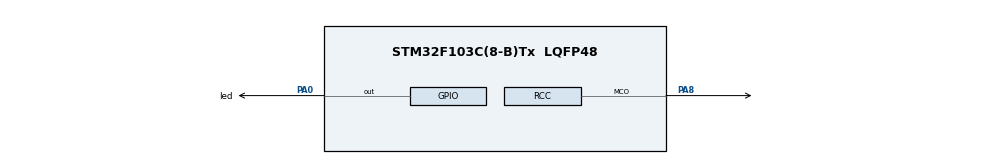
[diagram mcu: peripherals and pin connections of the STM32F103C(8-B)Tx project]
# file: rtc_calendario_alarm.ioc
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Mcu.Family=STM32F1
Mcu.Name=STM32F103C(8-B)Tx
Mcu.Package=LQFP48
NVIC.PriorityGroup=NVIC_PRIORITYGROUP_4
PA0-WKUP.GPIO_Label=led
PA0-WKUP.Signal=GPIO_Output
PA8.Mode=Clock-out
PA8.Signal=RCC_MCO
PC14-OSC32_IN.Mode=LSE-External-Oscillator
PC14-OSC32_IN.Signal=RCC_OSC32_IN
PC15-OSC32_OUT.Mode=LSE-External-Oscillator
PC15-OSC32_OUT.Signal=RCC_OSC32_OUT
ProjectManager.HeapSize=0x200
ProjectManager.StackSize=0x400
ProjectManager.TargetToolchain=STM32CubeIDE
RCC.APB1Freq_Value=8000000
RCC.APB2Freq_Value=8000000
RCC.RTCClockSelection=RCC_RTCCLKSOURCE_LSE
RTC.Format=RTC_FORMAT_BIN
VP_RTC_VS_RTC_Activate.Mode=RTC_Enabled
VP_RTC_VS_RTC_Calendar.Mode=RTC_Calendar
board=custom

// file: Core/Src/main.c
/* USER CODE BEGIN Header */
/**
  ******************************************************************************
  * @file           : main.c
  * @brief          : Main program body
  ******************************************************************************
  * @attention
  *
  * Copyright (c) 2023 STMicroelectronics.
  * All rights reserved.
  *
  * This software is licensed under terms that can be found in the LICENSE file
  * in the root directory of this software component.
  * If no LICENSE file comes with this software, it is provided AS-IS.
  *
  ******************************************************************************
  */
/* USER CODE END Header */
#include "main.h"

RTC_HandleTypeDef hrtc;

/* USER CODE BEGIN PV */
RTC_DateTypeDef sData;
RTC_TimeTypeDef sTempo;
uint8_t dia;
uint8_t semana;
uint8_t mes;
uint8_t ano;
uint8_t seg;
uint8_t min;
uint8_t hora;

/* USER CODE END PV */

void SystemClock_Config(void);
static void MX_GPIO_Init(void);
static void MX_RTC_Init(void);

int main(void)
{

  /* MCU Configuration--------------------------------------------------------*/

  /* Reset of all peripherals, Initializes the Flash interface and the Systick. */
  HAL_Init();

  /* Configure the system clock */
  SystemClock_Config();

  /* Initialize all configured peripherals */
  MX_GPIO_Init();
  MX_RTC_Init();
  /* USER CODE BEGIN 2 */
  sData.Date = 25;
  sData.Month = 5;
  sData.WeekDay = 6;
  sData.Year = 23;
  HAL_RTC_SetDate(&hrtc, &sData, FORMAT_BIN);

  sTempo.Seconds = 50;
  sTempo.Minutes = 59;
  sTempo.Hours = 23;
  HAL_RTC_SetTime(&hrtc, &sTempo, FORMAT_BIN);

  /* USER CODE END 2 */

  /* Infinite loop */
  /* USER CODE BEGIN WHILE */
  while (1)
  {
	  HAL_RTC_GetDate(&hrtc, &sData, FORMAT_BIN);
	  dia = sData.Date;
	  HAL_RTC_GetDate(&hrtc, &sData, FORMAT_BIN);
	  mes = sData.Month;
	  HAL_RTC_GetDate(&hrtc, &sData, FORMAT_BIN);
	  semana = sData.WeekDay;
	  HAL_RTC_GetDate(&hrtc, &sData, FORMAT_BIN);
	  ano = sData.Year;

	  HAL_RTC_GetTime(&hrtc, &sTempo, FORMAT_BIN);
	  seg = sTempo.Seconds;
	  HAL_RTC_GetTime(&hrtc, &sTempo, FORMAT_BIN);
	  min = sTempo.Minutes;
	  HAL_RTC_GetTime(&hrtc, &sTempo, FORMAT_BIN);
	  ano = sTempo.Hours;

	  if(seg == 0){
		  HAL_GPIO_WritePin(GPIOA,led_Pin, 1);
	  }
	  if(seg == 1){
		  HAL_GPIO_WritePin(GPIOA,led_Pin, 0);
	  }

    /* USER CODE END WHILE */

  }
}

void SystemClock_Config(void)
{
  RCC_OscInitTypeDef RCC_OscInitStruct = {0};
  RCC_ClkInitTypeDef RCC_ClkInitStruct = {0};
  RCC_PeriphCLKInitTypeDef PeriphClkInit = {0};

  /** Initializes the RCC Oscillators according to the specified parameters
  * in the RCC_OscInitTypeDef structure.
  */
  RCC_OscInitStruct.OscillatorType = RCC_OSCILLATORTYPE_HSI|RCC_OSCILLATORTYPE_LSE;
  RCC_OscInitStruct.LSEState = RCC_LSE_ON;
  RCC_OscInitStruct.HSIState = RCC_HSI_ON;
  RCC_OscInitStruct.HSICalibrationValue = RCC_HSICALIBRATION_DEFAULT;
  RCC_OscInitStruct.PLL.PLLState = RCC_PLL_NONE;
  if (HAL_RCC_OscConfig(&RCC_OscInitStruct) != HAL_OK)
  {
    Error_Handler();
  }

  /** Initializes the CPU, AHB and APB buses clocks
  */
  RCC_ClkInitStruct.ClockType = RCC_CLOCKTYPE_HCLK|RCC_CLOCKTYPE_SYSCLK
                              |RCC_CLOCKTYPE_PCLK1|RCC_CLOCKTYPE_PCLK2;
  RCC_ClkInitStruct.SYSCLKSource = RCC_SYSCLKSOURCE_HSI;
  RCC_ClkInitStruct.AHBCLKDivider = RCC_SYSCLK_DIV1;
  RCC_ClkInitStruct.APB1CLKDivider = RCC_HCLK_DIV1;
  RCC_ClkInitStruct.APB2CLKDivider = RCC_HCLK_DIV1;

  if (HAL_RCC_ClockConfig(&RCC_ClkInitStruct, FLASH_LATENCY_0) != HAL_OK)
  {
    Error_Handler();
  }
  PeriphClkInit.PeriphClockSelection = RCC_PERIPHCLK_RTC;
  PeriphClkInit.RTCClockSelection = RCC_RTCCLKSOURCE_LSE;
  if (HAL_RCCEx_PeriphCLKConfig(&PeriphClkInit) != HAL_OK)
  {
    Error_Handler();
  }
  HAL_RCC_MCOConfig(RCC_MCO, RCC_MCO1SOURCE_SYSCLK, RCC_MCODIV_1);
}

static void MX_RTC_Init(void)
{

  RTC_TimeTypeDef sTime = {0};
  RTC_DateTypeDef DateToUpdate = {0};

  /** Initialize RTC Only
  */
  hrtc.Instance = RTC;
  hrtc.Init.AsynchPrediv = RTC_AUTO_1_SECOND;
  hrtc.Init.OutPut = RTC_OUTPUTSOURCE_ALARM;
  if (HAL_RTC_Init(&hrtc) != HAL_OK)
  {
    Error_Handler();
  }

  /** Initialize RTC and set the Time and Date
  */
  sTime.Hours = 0;
  sTime.Minutes = 0;
  sTime.Seconds = 0;

  if (HAL_RTC_SetTime(&hrtc, &sTime, RTC_FORMAT_BIN) != HAL_OK)
  {
    Error_Handler();
  }
  DateToUpdate.WeekDay = RTC_WEEKDAY_MONDAY;
  DateToUpdate.Month = RTC_MONTH_JANUARY;
  DateToUpdate.Date = 1;
  DateToUpdate.Year = 0;

  if (HAL_RTC_SetDate(&hrtc, &DateToUpdate, RTC_FORMAT_BIN) != HAL_OK)
  {
    Error_Handler();
  }

}

static void MX_GPIO_Init(void)
{
  GPIO_InitTypeDef GPIO_InitStruct = {0};

  /* GPIO Ports Clock Enable */
  __HAL_RCC_GPIOC_CLK_ENABLE();
  __HAL_RCC_GPIOA_CLK_ENABLE();

  /*Configure GPIO pin Output Level */
  HAL_GPIO_WritePin(led_GPIO_Port, led_Pin, GPIO_PIN_RESET);

  /*Configure GPIO pin : led_Pin */
  GPIO_InitStruct.Pin = led_Pin;
  GPIO_InitStruct.Mode = GPIO_MODE_OUTPUT_PP;
  GPIO_InitStruct.Pull = GPIO_NOPULL;
  GPIO_InitStruct.Speed = GPIO_SPEED_FREQ_LOW;
  HAL_GPIO_Init(led_GPIO_Port, &GPIO_InitStruct);

  /*Configure GPIO pin : PA8 */
  GPIO_InitStruct.Pin = GPIO_PIN_8;
  GPIO_InitStruct.Mode = GPIO_MODE_AF_PP;
  GPIO_InitStruct.Speed = GPIO_SPEED_FREQ_LOW;
  HAL_GPIO_Init(GPIOA, &GPIO_InitStruct);

}

void Error_Handler(void)
{
  __disable_irq();
  while (1)
  {
  }
}
